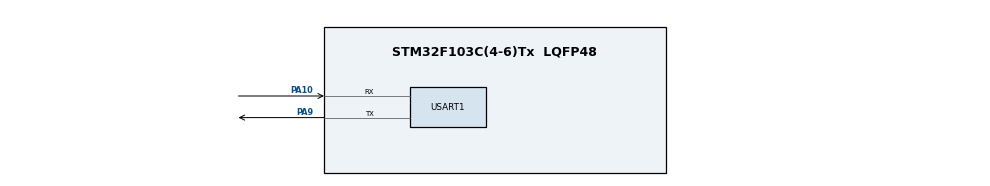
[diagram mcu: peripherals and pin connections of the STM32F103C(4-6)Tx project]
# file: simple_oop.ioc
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FREERTOS.Tasks01=mainTask,24,128,StartMainTask,Default,NULL,Dynamic,NULL,NULL
FREERTOS.configUSE_NEWLIB_REENTRANT=1
Mcu.Family=STM32F1
Mcu.Name=STM32F103C(4-6)Tx
Mcu.Package=LQFP48
NVIC.PriorityGroup=NVIC_PRIORITYGROUP_4
NVIC.TIM1_UP_IRQn=true\:15\:0\:false\:false\:true\:false\:false\:true\:true
NVIC.TimeBase=TIM1_UP_IRQn
NVIC.TimeBaseIP=TIM1
PA10.Mode=Asynchronous
PA10.Signal=USART1_RX
PA9.Mode=Asynchronous
PA9.Signal=USART1_TX
ProjectManager.HeapSize=0x200
ProjectManager.StackSize=0x400
ProjectManager.TargetToolchain=STM32CubeIDE
RCC.APB1Freq_Value=8000000
RCC.APB2Freq_Value=8000000
USART1.VirtualMode=VM_ASYNC
VP_FREERTOS_VS_CMSIS_V2.Mode=CMSIS_V2
VP_SYS_VS_tim1.Mode=TIM1
board=custom

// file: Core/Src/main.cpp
/* USER CODE BEGIN Header */
/**
 ******************************************************************************
 * @file           : main.c
 * @brief          : Main program body
 ******************************************************************************
 * @attention
 *
 * Copyright (c) 2023 STMicroelectronics.
 * All rights reserved.
 *
 * This software is licensed under terms that can be found in the LICENSE file
 * in the root directory of this software component.
 * If no LICENSE file comes with this software, it is provided AS-IS.
 *
 ******************************************************************************
 */
/* USER CODE END Header */
#include "main.h"
#include "cmsis_os.h"

/* USER CODE BEGIN Includes */
#include "car.h"
#include <string.h>
#include <utilities.h>
/* USER CODE END Includes */

UART_HandleTypeDef huart1;

/* Definitions for mainTask */
osThreadId_t mainTaskHandle;
const osThreadAttr_t mainTask_attributes = {
		.name = "mainTask",
		.stack_size = 128 * 4,
		.priority = (osPriority_t) osPriorityNormal,
};

void SystemClock_Config(void);
static void MX_GPIO_Init(void);
static void MX_USART1_UART_Init(void);
void StartMainTask(void *argument);

int main(void)
{

	/* MCU Configuration--------------------------------------------------------*/

	/* Reset of all peripherals, Initializes the Flash interface and the Systick. */
	HAL_Init();

	/* Configure the system clock */
	SystemClock_Config();

	/* Initialize all configured peripherals */
	MX_GPIO_Init();
	MX_USART1_UART_Init();

	/* Init scheduler */
	osKernelInitialize();

	/* Create the thread(s) */
	/* creation of mainTask */
	mainTaskHandle = osThreadNew(StartMainTask, NULL, &mainTask_attributes);

	/* Start scheduler */
	osKernelStart();

	/* We should never get here as control is now taken by the scheduler */
	/* Infinite loop */
	while (1)
	{

	}
}

void SystemClock_Config(void)
{
	RCC_OscInitTypeDef RCC_OscInitStruct = {0};
	RCC_ClkInitTypeDef RCC_ClkInitStruct = {0};

	/** Initializes the RCC Oscillators according to the specified parameters
	 * in the RCC_OscInitTypeDef structure.
	 */
	RCC_OscInitStruct.OscillatorType = RCC_OSCILLATORTYPE_HSI;
	RCC_OscInitStruct.HSIState = RCC_HSI_ON;
	RCC_OscInitStruct.HSICalibrationValue = RCC_HSICALIBRATION_DEFAULT;
	RCC_OscInitStruct.PLL.PLLState = RCC_PLL_NONE;
	if (HAL_RCC_OscConfig(&RCC_OscInitStruct) != HAL_OK)
	{
		Error_Handler();
	}

	/** Initializes the CPU, AHB and APB buses clocks
	 */
	RCC_ClkInitStruct.ClockType = RCC_CLOCKTYPE_HCLK|RCC_CLOCKTYPE_SYSCLK
			|RCC_CLOCKTYPE_PCLK1|RCC_CLOCKTYPE_PCLK2;
	RCC_ClkInitStruct.SYSCLKSource = RCC_SYSCLKSOURCE_HSI;
	RCC_ClkInitStruct.AHBCLKDivider = RCC_SYSCLK_DIV1;
	RCC_ClkInitStruct.APB1CLKDivider = RCC_HCLK_DIV1;
	RCC_ClkInitStruct.APB2CLKDivider = RCC_HCLK_DIV1;

	if (HAL_RCC_ClockConfig(&RCC_ClkInitStruct, FLASH_LATENCY_0) != HAL_OK)
	{
		Error_Handler();
	}
}

static void MX_USART1_UART_Init(void)
{

	huart1.Instance = USART1;
	huart1.Init.BaudRate = 115200;
	huart1.Init.WordLength = UART_WORDLENGTH_8B;
	huart1.Init.StopBits = UART_STOPBITS_1;
	huart1.Init.Parity = UART_PARITY_NONE;
	huart1.Init.Mode = UART_MODE_TX_RX;
	huart1.Init.HwFlowCtl = UART_HWCONTROL_NONE;
	huart1.Init.OverSampling = UART_OVERSAMPLING_16;
	if (HAL_UART_Init(&huart1) != HAL_OK)
	{
		Error_Handler();
	}

}

static void MX_GPIO_Init(void)
{

	/* GPIO Ports Clock Enable */
	__HAL_RCC_GPIOA_CLK_ENABLE();

}

/* USER CODE BEGIN 4 */

Car * new_car = new Car("Lamborghini", "Aventador SVJ", GASOLINE, 522948, 350, true);

/* USER CODE END 4 */

void StartMainTask(void *argument)
{
	/* USER CODE BEGIN 5 */
	/* Infinite loop */
	for(;;)
	{
		char buffer[15];

		uint8_t *brand = new_car->getBrand() ;
		uint8_t *model = new_car->getModel() ;
		uint8_t *fuel_type = new_car->getFuelType();

		int price = new_car->getPrice() ;
		itoa(price, buffer, 10);
		uint8_t * price_tag = (uint8_t *)buffer;
		price_tag = uint8Cat(price_tag, (uint8_t *)"$");

		int max_speed = new_car->getMaxSpeed() ;
		bool car_status = new_car->getStatus();

		convPrint(brand);
		convPrint(model);
		convPrint(fuel_type);
		convPrint(price_tag);
		convPrint(max_speed);
		convPrint(car_status);
		newLine();
		//		convPrint(100000);
		//		convPrint((uint8_t *)price);
		//		convPrint((uint8_t *)max_speed);
		osDelay(1000);
	}
	/* USER CODE END 5 */
}

void HAL_TIM_PeriodElapsedCallback(TIM_HandleTypeDef *htim)
{
	if (htim->Instance == TIM1) {
		HAL_IncTick();
	}
}

void Error_Handler(void)
{
	__disable_irq();
	while (1)
	{
	}
}
